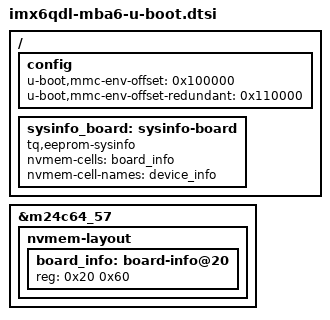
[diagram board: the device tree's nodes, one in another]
// SPDX-License-Identifier: (GPL-2.0-or-later OR MIT)
/*
 * Copyright (c) 2023-2026 TQ-Systems GmbH <u-boot@ew.tq-group.com>,
 * D-82229 Seefeld, Germany.
 * Author: Markus Niebel
 */

#include "imx6qdl-tqma6-u-boot.dtsi"
/ {
	config {
		u-boot,mmc-env-offset = <0x100000>;
		u-boot,mmc-env-offset-redundant = <0x110000>;
	};

	sysinfo_board: sysinfo-board {
		compatible = "tq,eeprom-sysinfo";
		nvmem-cells = <&board_info>;
		nvmem-cell-names = "device_info";
	};
};

&m24c64_57 {
	nvmem-layout {
		board_info: board-info@20 {
			reg = <0x20 0x60>;
		};
	};
};
